# npck3m7k register map
Registers are 8-bit, read-write, no defined reset value unless marked. A register's access mark holds for its fields unless they carry their own. Offsets are from the block's base; [hi:lo] are bit positions; {n}, {i} and the like mark numbered series.

## SPIP — SPI Peripheral Interface Module
Base 0x400D2000
0x00 SPIP_DATA 16-bit
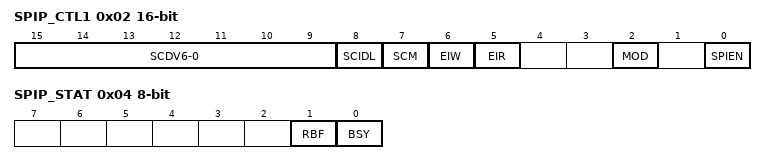
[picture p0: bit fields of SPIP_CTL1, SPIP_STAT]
0x02 SPIP_CTL1 16-bit
  [15:9] SCDV6-0, [8] SCIDL, [7] SCM, [6] EIW, [5] EIR, [2] MOD, [0] SPIEN
0x04 SPIP_STAT
  [1] RBF, [0] BSY
0x08 SPIP_TEST 16-bit
  [0] TB
0x0E SPIP_VER

## SPIP2 — SPI Peripheral Interface Module
Base 0x400D0000
Registers as SPIP (with SPIP read as SPIP2).

## SHI — Serial Host Interface Module
Base 0x4000B000
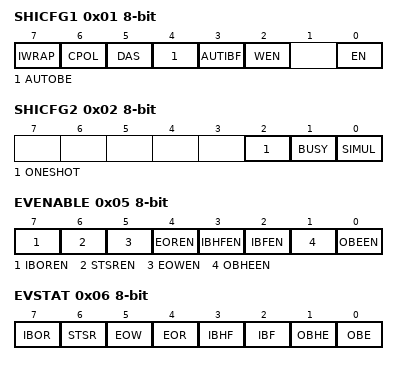
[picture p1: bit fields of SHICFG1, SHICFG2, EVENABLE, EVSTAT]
0x01 SHICFG1
  [7] IWRAP, [6] CPOL, [5] DAS, [4] AUTOBE, [3] AUTIBF, [2] WEN, [0] EN
0x02 SHICFG2
  [2] ONESHOT, [1] BUSY, [0] SIMUL
0x05 EVENABLE
  [7] IBOREN, [6] STSREN, [5] EOWEN, [4] EOREN, [3] IBHFEN, [2] IBFEN, [1] OBHEEN, [0] OBEEN
0x06 EVSTAT
  [7] IBOR, [6] STSR, [5] EOW, [4] EOR, [3] IBHF, [2] IBF, [1] OBHE, [0] OBE
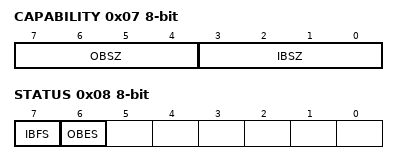
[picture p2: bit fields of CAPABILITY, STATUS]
0x07 CAPABILITY
  [7:4] OBSZ, [3:0] IBSZ
0x08 STATUS
  [7] IBFS, [6] OBES
0x0A IBUFSTAT
0x0B OBUFSTAT

## OBUF0-7
Base 0x4000B000
{0x20+i} OBUF{i:02} (i=0..7)

## OBUF8-15
Base 0x4000B000
{0x20+i} OBUF{i:02} (i=8..15)

## OBUF16-23
Base 0x4000B000
{0x20+i} OBUF{i} (i=16..23)

## OBUF24-31
Base 0x4000B000
{0x20+i} OBUF{i} (i=24..31)

## OBUF32-39
Base 0x4000B000
{0x20+i} OBUF{i} (i=32..39)

## OBUF40-47
Base 0x4000B000
{0x20+i} OBUF{i} (i=40..47)

## OBUF48-55
Base 0x4000B000
{0x20+i} OBUF{i} (i=48..55)

## OBUF56-63
Base 0x4000B000
{0x20+i} OBUF{i} (i=56..63)

## IBUF0-7
Base 0x4000B000
{0x60+i} IBUF{i:02} (i=0..7)

## IBUF8-15
Base 0x4000B000
{0x60+i} IBUF{i:02} (i=8..15)

## IBUF16-23
Base 0x4000B000
{0x60+i} IBUF{i} (i=16..23)

## IBUF24-31
Base 0x4000B000
{0x60+i} IBUF{i} (i=24..31)

## IBUF32-39
Base 0x4000B000
{0x60+i} IBUF{i} (i=32..39)

## IBUF40-47
Base 0x4000B000
{0x60+i} IBUF{i} (i=40..47)

## IBUF48-55
Base 0x4000B000
{0x60+i} IBUF{i} (i=48..55)

## IBUF56-63
Base 0x4000B000
{0x60+i} IBUF{i} (i=56..63)

## BBRM — Battery-Backed RAM
Base 0x400AF100
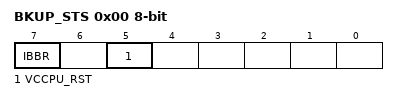
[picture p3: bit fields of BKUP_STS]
0x00 BKUP_STS
  [7] IBBR, [5] VCCPU_RST

## BBRM_DATA — memory data
Base 0x400AF000
{0x0+i} BRAM{i:02} (i=0..9)
{0xA+0x10*i} BRAM{i}A (i=0..3)
{0xB+0x10*i} BRAM{i}B (i=0..3)
{0xC+0x10*i} BRAM{i}C (i=0..3)
{0xD+0x10*i} BRAM{i}D (i=0..3)
{0xE+0x10*i} BRAM{i}E (i=0..3)
{0xF+0x10*i} BRAM{i}F (i=0..3)
{0x6+i} BRAM{i} (i=10..19)
{0xC+i} BRAM{i} (i=20..29)
{0x12+i} BRAM{i} (i=30..39)

## AES — AES Module
Base 0x40002000
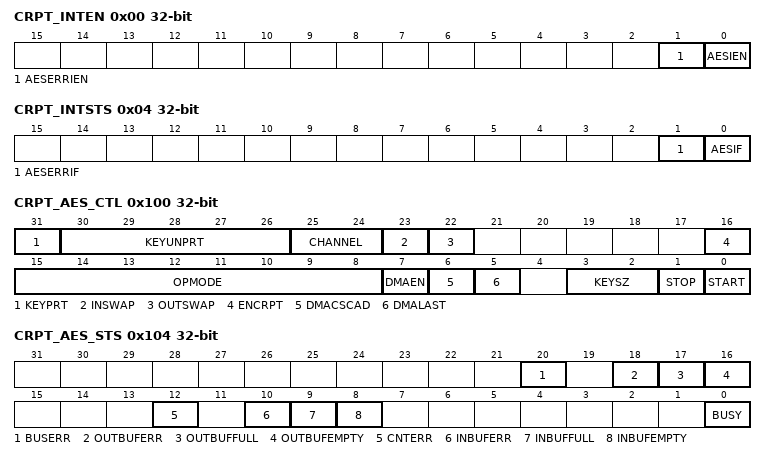
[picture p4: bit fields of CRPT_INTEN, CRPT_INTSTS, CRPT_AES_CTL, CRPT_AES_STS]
0x00 CRPT_INTEN 32-bit
  [1] AESERRIEN, [0] AESIEN
0x04 CRPT_INTSTS 32-bit
  [1] AESERRIF, [0] AESIF
{0x50+4i} CRPT_AES_FDBCK{i} 32-bit (i=0..3)
0x100 CRPT_AES_CTL 32-bit
  [31] KEYPRT, [30:26] KEYUNPRT, [25:24] CHANNEL, [23] INSWAP, [22] OUTSWAP, [16] ENCRPT, [15:8] OPMODE, [7] DMAEN, [6] DMACSCAD, [5] DMALAST, [3:2] KEYSZ, [1] STOP, [0] START
0x104 CRPT_AES_STS 32-bit
  [20] BUSERR, [18] OUTBUFERR, [17] OUTBUFFULL, [16] OUTBUFEMPTY, [12] CNTERR, [10] INBUFERR, [9] INBUFFULL, [8] INBUFEMPTY, [0] BUSY
0x108 CRPT_AES_DATIN 32-bit
0x10C CRPT_AES_DATOUT 32-bit
{0x110+4i} CRPT_AES_KEY{i} 32-bit (i=0..7)
{0x130+4i} CRPT_AES_IV{i} 32-bit (i=0..3)
0x140 CRPT_AES_SADDR 32-bit
0x144 CRPT_AES_DADDR 32-bit
0x148 CRPT_AES_CNT 32-bit
0xFEC AES_VER 32-bit
  [7:0] AES_VER

## PKA — Public Key Accelerator Module
Base 0x40001000
0x14 PKA_VER 32-bit
  [7:0] PKA_VER
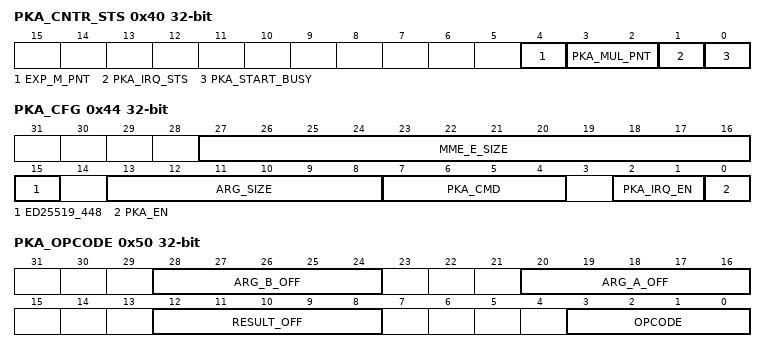
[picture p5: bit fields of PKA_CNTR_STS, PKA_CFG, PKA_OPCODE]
0x40 PKA_CNTR_STS 32-bit
  [4] EXP_M_PNT, [3:2] PKA_MUL_PNT, [1] PKA_IRQ_STS, [0] PKA_START_BUSY
0x44 PKA_CFG 32-bit
  [27:16] MME_E_SIZE, [15] ED25519_448, [13:8] ARG_SIZE, [7:4] PKA_CMD, [2:1] PKA_IRQ_EN, [0] PKA_EN
0x48 MME_J0 32-bit
0x50 PKA_OPCODE 32-bit
  [28:24] ARG_B_OFF, [20:16] ARG_A_OFF, [12:8] RESULT_OFF, [3:0] OPCODE

## SHA1-2 — SHA1-2 Hash Engine Module
Base 0x40000000
0x00 HASH_DATA_IN 32-bit
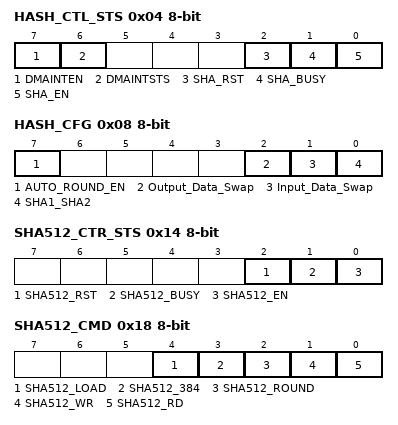
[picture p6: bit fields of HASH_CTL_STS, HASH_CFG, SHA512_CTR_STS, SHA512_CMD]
0x04 HASH_CTL_STS
  [7] DMAINTEN, [6] DMAINTSTS, [2] SHA_RST, [1] SHA_BUSY, [0] SHA_EN
0x08 HASH_CFG
  [7] AUTO_ROUND_EN, [2] Output_Data_Swap, [1] Input_Data_Swap, [0] SHA1_SHA2
0x0C HASH_VER
0x14 SHA512_CTR_STS
  [2] SHA512_RST, [1] SHA512_BUSY, [0] SHA512_EN
0x18 SHA512_CMD
  [4] SHA512_LOAD, [3] SHA512_384, [2] SHA512_ROUND, [1] SHA512_WR, [0] SHA512_RD
{0x20+4i} HASH_DIG_H_{i} 32-bit (i=0..7)

## RNG — Random Number Generator Module
Base 0x400D9000
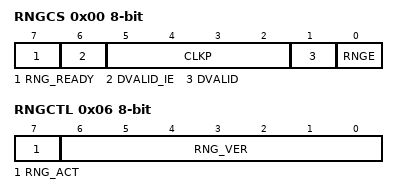
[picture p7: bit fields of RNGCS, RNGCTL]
0x00 RNGCS
  [7] RNG_READY, [6] DVALID_IE, [5:2] CLKP, [1] DVALID, [0] RNGE
0x02 RNGD
0x06 RNGCTL
  [7] RNG_ACT, [6:0] RNG_VER
